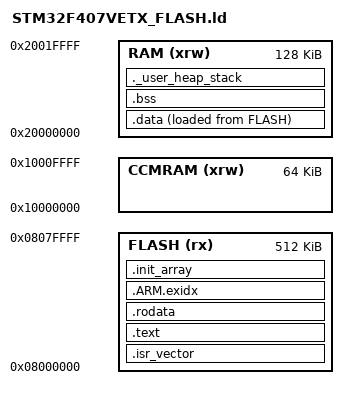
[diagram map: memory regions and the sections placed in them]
/* STM32F407VETx: 512 KB flash, 128 KB SRAM (+64 KB CCM, unused). Same layout as CubeIDE's. */
ENTRY(Reset_Handler)

_Min_Heap_Size = 0x200;
_Min_Stack_Size = 0x400;

MEMORY
{
  CCMRAM (xrw) : ORIGIN = 0x10000000, LENGTH = 64K
  RAM    (xrw) : ORIGIN = 0x20000000, LENGTH = 128K
  FLASH  (rx)  : ORIGIN = 0x08000000, LENGTH = 512K
}

_estack = ORIGIN(RAM) + LENGTH(RAM);

SECTIONS
{
  .isr_vector : { . = ALIGN(4); KEEP(*(.isr_vector)) . = ALIGN(4); } >FLASH

  .text :
  {
    . = ALIGN(4);
    *(.text) *(.text*) *(.glue_7) *(.glue_7t) *(.eh_frame)
    KEEP (*(.init)) KEEP (*(.fini))
    . = ALIGN(4);
    _etext = .;
  } >FLASH

  .rodata : { . = ALIGN(4); *(.rodata) *(.rodata*) . = ALIGN(4); } >FLASH
  .ARM.exidx : { *(.ARM.exidx* .gnu.linkonce.armexidx.*) } >FLASH

  .init_array : { PROVIDE_HIDDEN (__init_array_start = .); KEEP (*(SORT(.init_array.*))) KEEP (*(.init_array*)) PROVIDE_HIDDEN (__init_array_end = .); } >FLASH

  _sidata = LOADADDR(.data);

  .data :
  {
    . = ALIGN(4);
    _sdata = .;
    *(.data) *(.data*)
    . = ALIGN(4);
    _edata = .;
  } >RAM AT> FLASH

  .bss (NOLOAD) :
  {
    . = ALIGN(4);
    _sbss = .;
    __bss_start__ = _sbss;
    *(.bss) *(.bss*) *(COMMON)
    . = ALIGN(4);
    _ebss = .;
    __bss_end__ = _ebss;
  } >RAM

  ._user_heap_stack (NOLOAD) :
  {
    . = ALIGN(8);
    PROVIDE ( end = . );
    . = . + _Min_Heap_Size;
    . = . + _Min_Stack_Size;
    . = ALIGN(8);
  } >RAM

  /DISCARD/ : { *(.ARM.attributes) }
}
